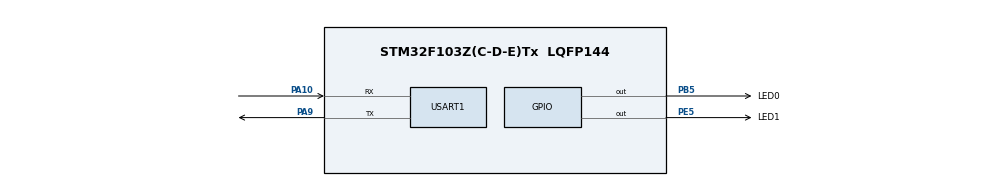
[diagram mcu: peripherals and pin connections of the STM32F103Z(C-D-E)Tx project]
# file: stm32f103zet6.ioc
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Dma.Request0=USART1_RX
Dma.Request1=USART1_TX
Dma.USART1_RX.0.Direction=DMA_PERIPH_TO_MEMORY
Dma.USART1_RX.0.Instance=DMA1_Channel5
Dma.USART1_RX.0.MemDataAlignment=DMA_MDATAALIGN_BYTE
Dma.USART1_RX.0.MemInc=DMA_MINC_ENABLE
Dma.USART1_RX.0.Mode=DMA_CIRCULAR
Dma.USART1_RX.0.PeriphDataAlignment=DMA_PDATAALIGN_BYTE
Dma.USART1_RX.0.PeriphInc=DMA_PINC_DISABLE
Dma.USART1_RX.0.Priority=DMA_PRIORITY_HIGH
Dma.USART1_TX.1.Direction=DMA_MEMORY_TO_PERIPH
Dma.USART1_TX.1.Instance=DMA1_Channel4
Dma.USART1_TX.1.MemDataAlignment=DMA_MDATAALIGN_BYTE
Dma.USART1_TX.1.MemInc=DMA_MINC_ENABLE
Dma.USART1_TX.1.Mode=DMA_NORMAL
Dma.USART1_TX.1.PeriphDataAlignment=DMA_PDATAALIGN_BYTE
Dma.USART1_TX.1.PeriphInc=DMA_PINC_DISABLE
Dma.USART1_TX.1.Priority=DMA_PRIORITY_MEDIUM
Mcu.Family=STM32F1
Mcu.Name=STM32F103Z(C-D-E)Tx
Mcu.Package=LQFP144
NVIC.DMA1_Channel4_IRQn=true\:0\:0\:false\:false\:true\:false\:true\:true
NVIC.DMA1_Channel5_IRQn=true\:0\:0\:false\:false\:true\:false\:true\:true
NVIC.PriorityGroup=NVIC_PRIORITYGROUP_4
NVIC.TIM6_IRQn=true\:2\:0\:true\:false\:true\:true\:true\:true
NVIC.USART1_IRQn=true\:1\:0\:true\:false\:true\:true\:true\:true
OSC_IN.Mode=HSE-External-Oscillator
OSC_IN.Signal=RCC_OSC_IN
OSC_OUT.Mode=HSE-External-Oscillator
OSC_OUT.Signal=RCC_OSC_OUT
PA10.Mode=Asynchronous
PA10.Signal=USART1_RX
PA13.Mode=Serial_Wire
PA13.Signal=SYS_JTMS-SWDIO
PA14.Mode=Serial_Wire
PA14.Signal=SYS_JTCK-SWCLK
PA9.Mode=Asynchronous
PA9.Signal=USART1_TX
PB5.GPIO_Label=LED0
PB5.GPIO_ModeDefaultOutputPP=GPIO_MODE_OUTPUT_PP
PB5.GPIO_PuPd=GPIO_PULLDOWN
PB5.GPIO_Speed=GPIO_SPEED_FREQ_MEDIUM
PB5.Signal=GPIO_Output
PE5.GPIO_Label=LED1
PE5.GPIO_PuPd=GPIO_PULLDOWN
PE5.GPIO_Speed=GPIO_SPEED_FREQ_MEDIUM
PE5.Signal=GPIO_Output
ProjectManager.HeapSize=0x200
ProjectManager.StackSize=0x400
ProjectManager.TargetToolchain=MDK-ARM V5.32
RCC.AHBFreq_Value=72000000
RCC.APB1CLKDivider=RCC_HCLK_DIV2
RCC.APB1Freq_Value=36000000
RCC.APB1TimFreq_Value=72000000
RCC.APB2Freq_Value=72000000
RCC.APB2TimFreq_Value=72000000
RCC.HCLKFreq_Value=72000000
RCC.PLLMUL=RCC_PLL_MUL9
RCC.PLLSourceVirtual=RCC_PLLSOURCE_HSE
RCC.SYSCLKFreq_VALUE=72000000
RCC.SYSCLKSource=RCC_SYSCLKSOURCE_PLLCLK
RCC.USBFreq_Value=72000000
TIM6.AutoReloadPreload=TIM_AUTORELOAD_PRELOAD_ENABLE
TIM6.Period=999
TIM6.Prescaler=71
USART1.VirtualMode=VM_ASYNC
VP_TIM6_VS_ClockSourceINT.Mode=Enable_Timer
board=custom

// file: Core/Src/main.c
/* USER CODE BEGIN Header */
/**
  ******************************************************************************
  * @file           : main.c
  * @brief          : Main program body
  ******************************************************************************
  * @attention
  *
  * Copyright (c) 2025 STMicroelectronics.
  * All rights reserved.
  *
  * This software is licensed under terms that can be found in the LICENSE file
  * in the root directory of this software component.
  * If no LICENSE file comes with this software, it is provided AS-IS.
  *
  ******************************************************************************
  */
/* USER CODE END Header */
#include "main.h"
#include "dma.h"
#include "tim.h"
#include "usart.h"
#include "gpio.h"

/* USER CODE BEGIN Includes */
#include "myUsartDrive/myUsartDrive.h"
/* USER CODE END Includes */

void SystemClock_Config(void);

int main(void)
{
  /* USER CODE BEGIN 1 */
  uint32_t fre = 0;
  /* USER CODE END 1 */

  /* MCU Configuration--------------------------------------------------------*/

  /* Reset of all peripherals, Initializes the Flash interface and the Systick. */
  LL_APB2_GRP1_EnableClock(LL_APB2_GRP1_PERIPH_AFIO);
  LL_APB1_GRP1_EnableClock(LL_APB1_GRP1_PERIPH_PWR);

  /* System interrupt init*/
  NVIC_SetPriorityGrouping(NVIC_PRIORITYGROUP_4);

  /* SysTick_IRQn interrupt configuration */
  NVIC_SetPriority(SysTick_IRQn, NVIC_EncodePriority(NVIC_GetPriorityGrouping(),15, 0));

  /** NOJTAG: JTAG-DP Disabled and SW-DP Enabled
  */
  LL_GPIO_AF_Remap_SWJ_NOJTAG();

  /* Configure the system clock */
  SystemClock_Config();

  /* Initialize all configured peripherals */
  MX_GPIO_Init();
  MX_DMA_Init();
  MX_USART1_UART_Init();
  MX_TIM6_Init();
  /* USER CODE BEGIN 2 */
  USART1_Config();
  LL_TIM_EnableIT_UPDATE(TIM6); // 启动TIM6溢出中断
  LL_TIM_EnableCounter(TIM6);   // 启动TIM6
  /* USER CODE END 2 */

  /* Infinite loop */
  while (1)
  {

    /* USER CODE BEGIN 3 */
    if (fre % 100 == 0) {
        LL_GPIO_TogglePin(LED0_GPIO_Port,LED0_Pin);
    }

    USART1_Module_Run(); // 1.处理接收ringbuffer的消息。2.将发送ringbuffer的消息，使用DMA一次性发送出去。

    fre++;
    LL_mDelay(1);
  }
  /* USER CODE END 3 */
}

void SystemClock_Config(void)
{
  LL_FLASH_SetLatency(LL_FLASH_LATENCY_2);
  while(LL_FLASH_GetLatency()!= LL_FLASH_LATENCY_2)
  {
  }
  LL_RCC_HSE_Enable();

   /* Wait till HSE is ready */
  while(LL_RCC_HSE_IsReady() != 1)
  {

  }
  LL_RCC_PLL_ConfigDomain_SYS(LL_RCC_PLLSOURCE_HSE_DIV_1, LL_RCC_PLL_MUL_9);
  LL_RCC_PLL_Enable();

   /* Wait till PLL is ready */
  while(LL_RCC_PLL_IsReady() != 1)
  {

  }
  LL_RCC_SetAHBPrescaler(LL_RCC_SYSCLK_DIV_1);
  LL_RCC_SetAPB1Prescaler(LL_RCC_APB1_DIV_2);
  LL_RCC_SetAPB2Prescaler(LL_RCC_APB2_DIV_1);
  LL_RCC_SetSysClkSource(LL_RCC_SYS_CLKSOURCE_PLL);

   /* Wait till System clock is ready */
  while(LL_RCC_GetSysClkSource() != LL_RCC_SYS_CLKSOURCE_STATUS_PLL)
  {

  }
  LL_Init1msTick(72000000);
  LL_SetSystemCoreClock(72000000);
}

void Error_Handler(void)
{
  __disable_irq();
  while (1)
  {
  }
}
